# RL7005_IP_SVD register map
Vendor: Realtek
Registers are 32-bit, read-write, reset 0x0 unless marked. A register's access mark holds for its fields unless they carry their own. Offsets are from the block's base; [hi:lo] are bit positions; {n}, {i} and the like mark numbered series.

## CTC_REG
Base 0x40813000
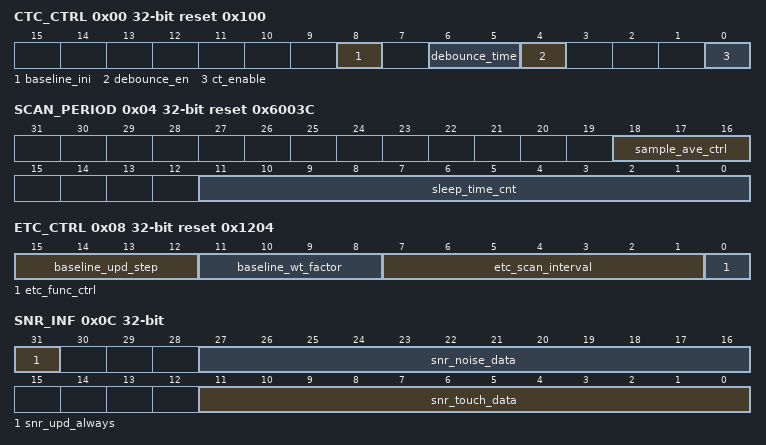
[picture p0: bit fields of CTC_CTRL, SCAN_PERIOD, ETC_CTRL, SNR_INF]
0x00 CTC_CTRL reset 0x100 — Captouch Control Register
  [8] baseline_ini — 1: Baseline initial function enable, HW will clear this bit to "0" after baseline initial
  [6:5] debounce_time — 2'b00: 2 times 2'b01: 3 times 2'b10: 4 times 2'b11: 5 times
  [4] debounce_en — 0: Disable 1: Enable
  [0] ct_enable — 0: CTC disable 1: CTC enable
0x04 SCAN_PERIOD reset 0x6003C — Scan Parameters Register
  [18:16] sample_ave_ctrl — ADC sampled number for average function average number=2^(sample_ave_ctrl+2)
  [11:0] sleep_time_cnt — Code: 0~4095 (0~0xFFF), unit is 1.024KHz cycle (1/32 32.768KHz). When this register is set to 0 , HW will scan continuously and have no sleep time. Recommend value: 60~480ms
0x08 ETC_CTRL reset 0x1204 — Environment Tracking Control Register
  [15:12] baseline_upd_step — Baseline update step for all channel
  [11:8] baseline_wt_factor — Baseline update weight factor (ETC_factor_th) for all channel ETC_factor_th=2^baseline_wt_factor
  [7:1] etc_scan_interval — ETC update interval between scan period (sleep time) for all channel Interval=(etc_scan_interval+1)*scan_period
  [0] etc_func_ctrl — Environmental cap tracking calibration function 0: Disable 1: Enable
0x0C SNR_INF — Signal Noise Ratio Register
  [31] snr_upd_always — 1: Update SNR info no matter touch or not (used only in debug function)
  [27:16] snr_noise_data — Noise peak to peak signal raw data for SNR monitor
  [11:0] snr_touch_data — Raw data of touch(signal-baseline)for SNR monitor
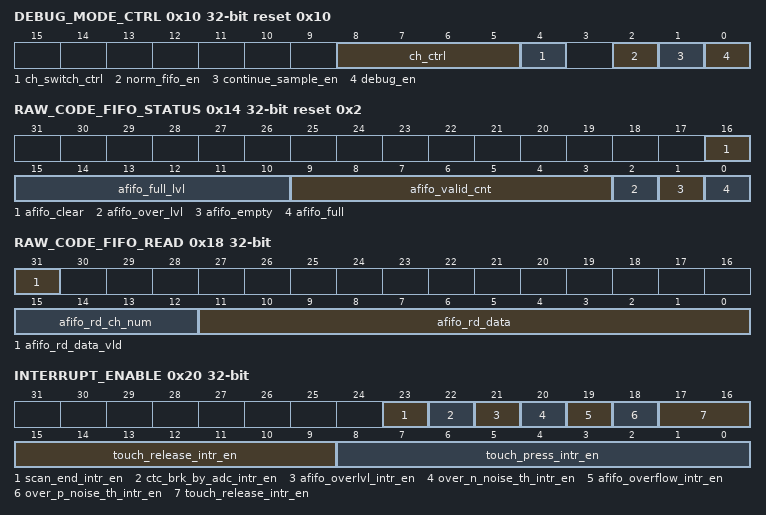
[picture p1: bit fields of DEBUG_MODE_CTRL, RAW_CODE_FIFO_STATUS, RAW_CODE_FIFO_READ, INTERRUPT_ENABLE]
0x10 DEBUG_MODE_CTRL reset 0x10 — Debug and Channel Swith Mode Register
  [8:5] ch_ctrl — Scan channel control 0000: channel 0 0001: channel 1 0010: channel 2 0011: channel 3 0100: channel 4 0101: channel 5 0110: channel 6 0111: channel 7 1000: channel 8
  [4] ch_switch_ctrl — Scan channel switch control 0: Auto switch function disable (manual switch by ch_ctrl) 1: Auto switch to next channel (channel 0 --> channel 3 --> channel 0)
  [2] norm_fifo_en — when debug mode disable, select whether to write the ctc processed data into the fifo 1: enable 0: disable
  [1] continue_sample_en — continue sample one channel mode enable, only take effect in debug mode 1: enable 0: disable
  [0] debug_en — Debug mode enable 0: Disable 1: Enable
0x14 RAW_CODE_FIFO_STATUS access per field reset 0x2 — FIFO Status Register
  [16] afifo_clear wo — clear the FIFO data
  [15:10] afifo_full_lvl rw — user define the full level for afifo, the valid value is from 0 to 63
  [9:3] afifo_valid_cnt ro — Raw code FIFO valid cnt(push unit number which can be read)
  [2] afifo_over_lvl ro — 0: Raw code FIFO not over level 1: Raw code FIFO over level
  [1] afifo_empty ro — 0: Raw code FIFO not empty 1: Raw code FIFO empty
  [0] afifo_full ro — 0: Raw code FIFO not oveflow (not full) 1: Raw code FIFO overflow(full)
0x18 RAW_CODE_FIFO_READ ro — FIFO Read Register
  [31] afifo_rd_data_vld — Read data from raw code FIFO valid
  [15:12] afifo_rd_ch_num — Read data from raw code FIFO [15:12] : channel number
  [11:0] afifo_rd_data — Read data from raw code FIFO [11:0] : data
0x20 INTERRUPT_ENABLE
  [23] scan_end_intr_en — sample scan finish enable
  [22] ctc_brk_by_adc_intr_en — captouch breaked by adc enable
  [21] afifo_overlvl_intr_en — Raw code FIFO over level enable
  [20] over_n_noise_th_intr_en — Negative noise threshold overflow enable
  [19] afifo_overflow_intr_en — Raw code FIFO overflow enable
  [18] over_p_noise_th_intr_en — Positive noise threshold overflow enable
  [17:9] touch_release_intr_en — Channelx single touch release enable, x is 0~8
  [8:0] touch_press_intr_en — Channelx single touch press enable, x is 0~8
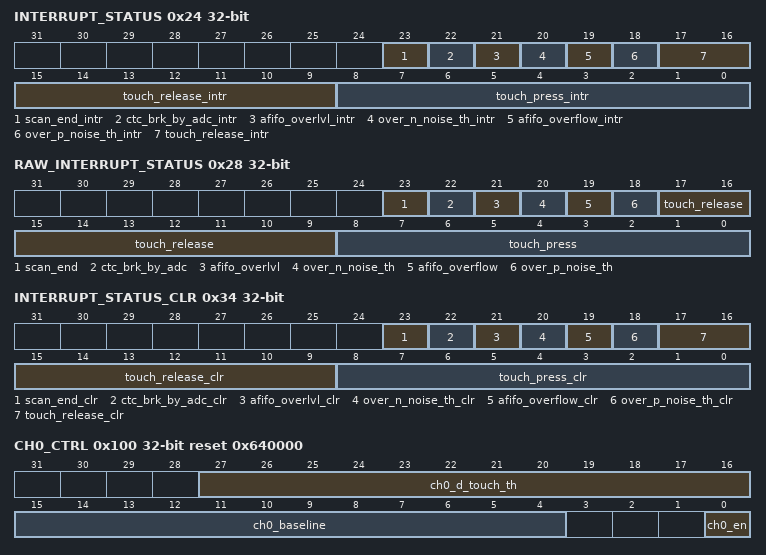
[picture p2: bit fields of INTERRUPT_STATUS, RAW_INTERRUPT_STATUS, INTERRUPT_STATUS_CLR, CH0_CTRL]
0x24 INTERRUPT_STATUS ro
  [23] scan_end_intr — sample scan finish interrupt
  [22] ctc_brk_by_adc_intr — captouch breaked by adc interrupt
  [21] afifo_overlvl_intr — Raw code FIFO over level interrupt
  [20] over_n_noise_th_intr — Negative noise threshold overflow interrupt
  [19] afifo_overflow_intr — Raw code FIFO overflow interrupt
  [18] over_p_noise_th_intr — Positive noise threshold overflow interrupt
  [17:9] touch_release_intr — Channelx single touch release interrupt, x is 0~8
  [8:0] touch_press_intr — Channelx single touch press interrupt, x is 0~8
0x28 RAW_INTERRUPT_STATUS ro
  [23] scan_end — sample scan finish raw interrupt
  [22] ctc_brk_by_adc — captouch breaked by adc raw interrupt
  [21] afifo_overlvl — Raw code FIFO over level raw interrupt
  [20] over_n_noise_th — Negative noise threshold overflow raw interrupt
  [19] afifo_overflow — Raw code FIFO overflow raw interrupt
  [18] over_p_noise_th — Positive noise threshold overflow raw interrupt
  [17:9] touch_release — Channelx single touch release raw interrupt, x is 0~8
  [8:0] touch_press — Channelx single touch press raw interrupt, x is 0~8
0x30 INTERRUPT_ALL_CLR — Interrupt All Clear Register
  [0] intr_all_clr — Write "1" to this register to clear the combined interrupts, all individual interrupts, interrupt status register and raw interrupt status register.
0x34 INTERRUPT_STATUS_CLR — Interrupt Clear Register
  [23] scan_end_clr — sample scan finish raw interrupt and related register
  [22] ctc_brk_by_adc_clr — Clear captouch breaked by adc raw interrupt and related register
  [21] afifo_overlvl_clr — Clear raw code FIFO over level raw interrupt and related register
  [20] over_n_noise_th_clr — Clear negative noise threshold overflow interrupt and related register
  [19] afifo_overflow_clr — Clear raw code FIFO overflow interrupt and related register
  [18] over_p_noise_th_clr — Clear positive noise threshold overflow interrupt and related register
  [17:9] touch_release_clr — Clear channelx single touch release interrupt and related register
  [8:0] touch_press_clr — Clear channelx single touch press interrupt and related register
0x40 DEBUG_SEL — Debug Select Register
  [2:0] dbg_sel — Debug information selection 0: dbg_clkrst 1: dbg_apbslv 2: dbg_ctrl 3: dbg_decision 4: dbg_adc_arb Others: dbg_clkrst
0x44 DEBUG_PORT ro — Debug Register
  [31:0] dbg_port — Debug port output value,depend on dbg_sel value
0x48 ECO_USE0
  [31:0] eco_use0 — For ECO use
0x4C ECO_USE1
  [31:0] eco_use1 — For ECO use
0x50 CTC_COMP_VERSION reset 0x20180123 — Version Register
  [31:0] comp_version — CTC version number
0x100 CH0_CTRL reset 0x640000 — Channel 0 Control Register
  [27:16] ch0_d_touch_th — Difference threshold data of touch judgement for channel 0. It needs to be configured during development, (0x0~0xFFF) (0~4095). Init number=0x1E Recommend data=80%*(signal-baseline)
  [15:4] ch0_baseline — Digital baseline data of channel 0. Init number=0x0 It can be initialed by HW when baseline initial function enabled, and can be updated automatically by HW when ETC function enabled. It could be configured by manual tuning.
  [0] ch0_en — Cap sensor activity control of channel 0 0: Disable 1: Enable
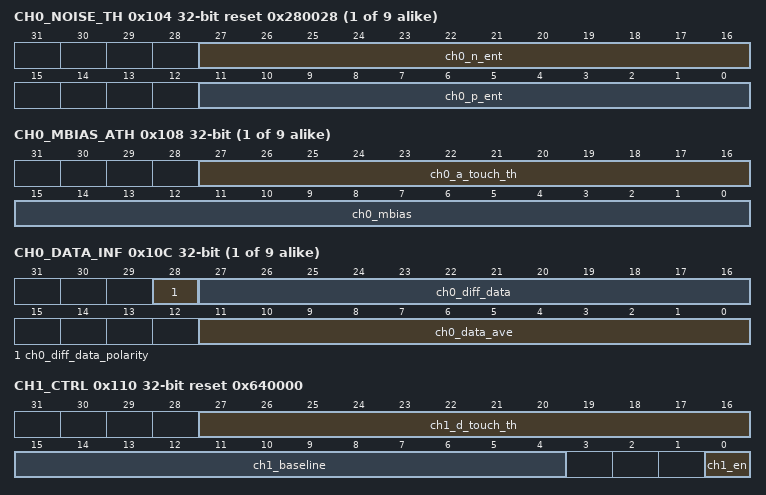
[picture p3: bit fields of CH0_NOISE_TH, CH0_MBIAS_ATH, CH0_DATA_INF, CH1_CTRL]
{0x104+0x10*i} CH{i}_NOISE_TH reset 0x280028 (i=0..8) — Channel {i} Noise Threshold Register
  [27:16] ch{i}_n_ent — The environmental negative noise threshold: the negative maximum capacitance change of raw data that is still considered an environment change.
  [11:0] ch{i}_p_ent — The environmental positive noise threshold: the positive maximum capacitance change of raw data that is still considered an environment change.
{0x108+0x10*i} CH{i}_MBIAS_ATH (i=0..8) — Channel {i} Mbias
  [27:16] ch{i}_a_touch_th — Absolute threshold data of touch judgement for channel {i}. It can be updated by HW when baseline initial function or ETC function enabled, a_touch_th=baseline-d_touch_th, manual tuning when ETC disabled, (0x0~0xFFF). Recommended data=80%*signal
  [15:0] ch{i}_mbias — 0/1/2/3/4/5/6/7/8/9/10/11/12/13/14/15: 0.25/0.25/0.25/0.25/0.5/0.5/1/2/2/4/8/8/16/32/32/64uA 0000000000000000:0uA 0000000000000001:0.25uA 0000000000000010:0.25uA ...1111111111111111:171uA
{0x10C+0x10*i} CH{i}_DATA_INF (i=0..8) — Channel {i} Dtouch Register
  [28] ch{i}_diff_data_polarity — Polarity of ch{i}_diff_data 0: ch{i}_data_ave<baseline 1: ch{i}_data_ave>=baseline
  [27:16] ch{i}_diff_data — Difference digital data of channel{i} between ch{i}_data_ave and baseline
  [11:0] ch{i}_data_ave — Average of channel {i} raw code
0x110 CH1_CTRL reset 0x640000 — Channel 0 Control Register
  [27:16] ch1_d_touch_th — Difference threshold data of touch judgement for channel 1. It needs to be configured during development, (0x0~0xFFF) (0~4095). Init number=0x1E Recommend data=80%*(signal-baseline)
  [15:4] ch1_baseline — Digital baseline data of channel 1. Init number=0x0 It can be initialed by HW when baseline initial function enabled, and can be updated automatically by HW when ETC function enabled. It could be configured by manual tuning.
  [0] ch1_en — Cap sensor activity control of channel 1 0: Disable 1: Enable
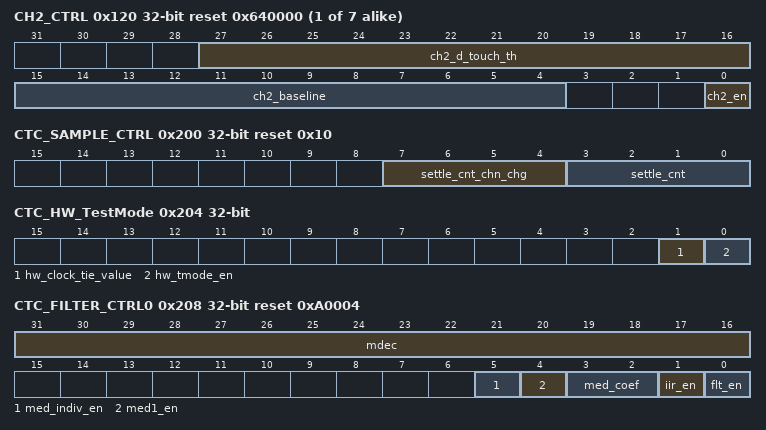
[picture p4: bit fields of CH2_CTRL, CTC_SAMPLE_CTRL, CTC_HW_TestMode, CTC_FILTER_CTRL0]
{0x100+0x10*i} CH{i}_CTRL reset 0x640000 (i=2..8) — Channel {i} Control Register
  [27:16] ch{i}_d_touch_th — Difference threshold data of touch judgement for channel {i}. It needs to be configured during development, (0x0~0xFFF) (0~4095). Init number=0x1E Recommend data=80%*(signal-baseline)
  [15:4] ch{i}_baseline — Digital baseline data of channel {i}. Init number=0x0 It can be initialed by HW when baseline initial function enabled, and can be updated automatically by HW when ETC function enabled. It could be configured by manual tuning.
  [0] ch{i}_en — Cap sensor activity control of channel {i} 0: Disable 1: Enable
0x200 CTC_SAMPLE_CTRL reset 0x10 — Captouch Sample Control Register
  [7:4] settle_cnt_chn_chg — settle count for sample data from chn switch, the unit is sample clock. 0 means no need to settle
  [3:0] settle_cnt — settle count for sample data from ADC to captouch, the unit is sample clock. 0 means no need to settle
0x204 CTC_HW_TestMode — Captouch_Hardware_Test_Mode Register
  [1] hw_clock_tie_value — this value is the clock tied value in captouch hardware test mode
  [0] hw_tmode_en — 0: hardware test mode disabled 1: hardware test mode enabled, the clock sent to AUX Analog from captouch is tie to fixed value, which is depent on hw_clock_tie_value( 410h[1] )
0x208 CTC_FILTER_CTRL0 reset 0xA0004 — Captouch Filter Control0 Register
  [31:16] mdec — Decimation of sample point
  [5] med_indiv_en — enable re-filters when each scan period. default state is continuous filter.
  [4] med1_en — Enable ctc data ave median filter function, median filter coefficient is 3.When ctc_clk_lcnt 0 / 1 / 2 fills in different values and med1 is enable, the filtering effect of aliasing fixed frequency interference can be enhanced.
  [3:2] med_coef — Median filter coefficient,for raw data 00:disable 01:coef is 3 10:coef is 5 11:coef is 7
  [1] iir_en — Enable ctc iir function,for raw data
  [0] flt_en — Enable ctc filter function(global),for raw data
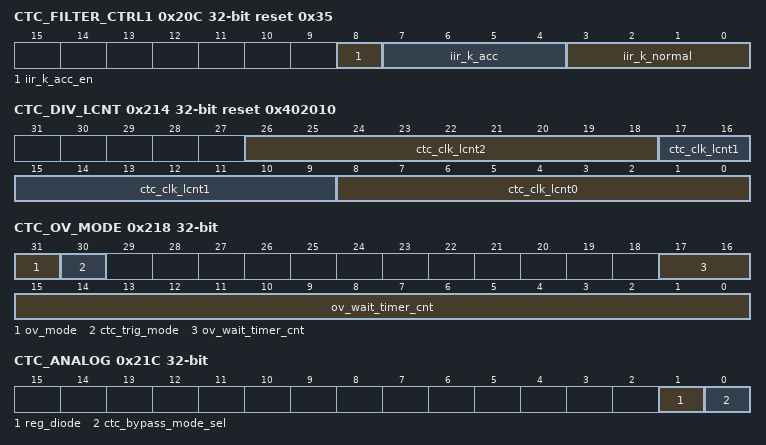
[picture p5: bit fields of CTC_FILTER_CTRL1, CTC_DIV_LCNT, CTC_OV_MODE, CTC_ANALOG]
0x20C CTC_FILTER_CTRL1 reset 0x35 — Captouch Filter Control1 Register
  [8] iir_k_acc_en — enable accelerated touch response.
  [7:4] iir_k_acc — iir filter coef. the range is 0~11.
  [3:0] iir_k_normal — iir filter coef. the range is 0~11.
0x210 CTC_DIV_HCNT reset 0xF — Captouch Div Hcnt Control Register
  [8:0] ctc_clk_hcnt — This field defines sample clock driver high level of chn. high level = (ctc_clk_hcnt +1)* ip_clk period
0x214 CTC_DIV_LCNT reset 0x402010 — Captouch Div Lcnt Control Register
  [26:18] ctc_clk_lcnt2 — This field defines sample clock driver lower level of chn. lower level = ctc_clk_lcnt2 * ip_clk period
  [17:9] ctc_clk_lcnt1 — This field defines sample clock driver lower level of chn. lower level = ctc_clk_lcnt1 * ip_clk period
  [8:0] ctc_clk_lcnt0 — This field defines sample clock driver lower level of chn lower level = ctc_clk_lcnt0 * ip_clk period
0x218 CTC_OV_MODE — Captouch Overmaple Mode Register
  [31] ov_mode — sample mode 1-All sample conversions done in staggered sequence 0-All sample conversions done in regular sequence
  [30] ctc_trig_mode — 0:ch_en trig 1: adc dummy chn trig
  [17:0] ov_wait_timer_cnt — when sample mode is taggered sequence,it determines how long to wait before starting the next periodic sampling after each chn has been sampled in turn. It can the unit is sample clock. When this register is set to 0 , HW will scan continuously and have no sleep time.
0x21C CTC_ANALOG — Captouch BYPASS Register
  [1] reg_diode — 1: enable diode
  [0] ctc_bypass_mode_sel — 0: divide_mode 1: bypass_mode
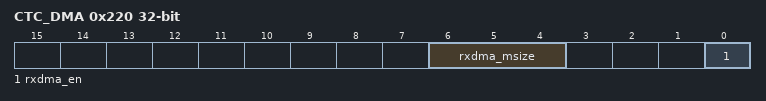
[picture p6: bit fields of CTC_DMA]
0x220 CTC_DMA — Captouch DMA Register
  [6:4] rxdma_msize — ctc rxdma burst size. When fifo reach certain entry depth , controller will req dma operation. 0: 1 entry 1: 4 2: 8 N: 2**(N+1) Note: this setting must be same with GDMA burst len , or fifo will underflow or overflow.
  [0] rxdma_en — 1:enable ctc rxdma Note: ctc dma interface must used GDMA as flow control , IP flow control is not support .
0x224 REG_CTC_DUMMY reset 0xF0 — Captouch Dummy Register
